# S32R372 register map
Vendor: Freescale Semiconductor, Inc.; Series: Qorivva; File version: 1.6
Registers are 32-bit, read-write, reset 0x0 unless marked. A register's access mark holds for its fields unless they carry their own. Offsets are from the block's base; [hi:lo] are bit positions; {n}, {i} and the like mark numbered series; 'fields as' and 'values as' point back to an identical list.

## PIT_1 — Periodic Interrupt Timer
Base 0xFFF80000; register names take the prefix PIT_1_
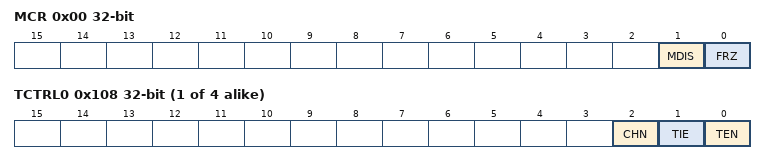
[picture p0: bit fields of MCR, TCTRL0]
0x00 MCR — PIT Module Control Register
  [1] MDIS — Module Disable - (PIT section)
    0=Clock for standard PIT timers is enabled; 1=Clock for standard PIT timers is disabled
  [0] FRZ — Freeze
    0=Timers continue to run in Debug mode; 1=Timers are stopped in Debug mode
0xE0 LTMR64H ro — PIT Upper Lifetime Timer Register
  [31:0] LTH — Life Timer value
0xE4 LTMR64L ro — PIT Lower Lifetime Timer Register
  [31:0] LTL — Life Timer value
{0x100+0x10*i} LDVAL{i} (i=0..3) — Timer Load Value Register
  [31:0] TSV — Timer Start Value
{0x104+0x10*i} CVAL{i} (i=0..3) ro — Current Timer Value Register
  [31:0] TVL — Current Timer Value
{0x108+0x10*i} TCTRL{i} (i=0..3) — Timer Control Register
  [2] CHN — Chain Mode
    0=Timer is not chained; 1=Timer is chained to previous timer. For example, for Channel 2, if this field is set, Timer 2 is chained to Timer 1.
  [1] TIE — Timer Interrupt Enable
    0=Interrupt requests from Timer n are disabled; 1=Interrupt will be requested whenever TIF is set
  [0] TEN — Timer Enable
    0=Timer n is disabled; 1=Timer n is enabled
{0x10C+0x10*i} TFLG{i} (i=0..3) — Timer Flag Register
  [0] TIF — Timer Interrupt Flag
    0=Timeout has not yet occurred; 1=Timeout has occurred

## PIT_0 — Periodic Interrupt Timer
Base 0xFFF84000; register names take the prefix PIT_0_
Registers as PIT_1.

## WKPU
Base 0xFFF98000; register names take the prefix WKPU_
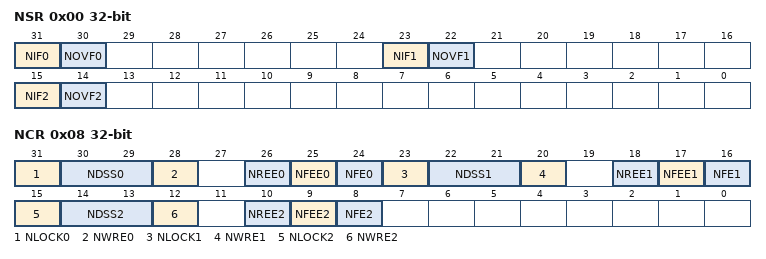
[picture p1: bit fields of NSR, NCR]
0x00 NSR — NMI Status Flag Register
  [31] NIF0 — NMI Status Flag 0
    0=No event has occurred on the pad; 1=An event as defined by NREE0 and NFEE0 has occurred
  [30] NOVF0 — NMI Overrun Status Flag 0
    0=No overrun has occurred on NMI input 0; 1=An overrun has occurred on NMI input 0
  [23] NIF1 — NMI Status Flag 1
    0=No event has occurred on the pad; 1=An event as defined by NREE1 and NFEE1 has occurred
  [22] NOVF1 — NMI Overrun Status Flag 1
    0=No overrun has occurred on NMI input 1; 1=An overrun has occurred on NMI input 1
  [15] NIF2 — NMI Status Flag 2
    0=No event has occurred on the pad; 1=An event as defined by NREE2 and NFEE2 has occurred
  [14] NOVF2 — NMI Overrun Status Flag 2
    0=No overrun has occurred on NMI input 2; 1=An overrun has occurred on NMI input 2
0x08 NCR — NMI Configuration Register
  [31] NLOCK0 — NMI Configuration Lock Register 0
  [30:29] NDSS0 — NMI Destination Source Select 0
    0=Non-maskable interrupt; 1=Critical interrupt; 2=Machine check request; 3=No NMI, critical Interrupt, or machine check request generated
  [28] NWRE0 — NMI Wakeup Request Enable 0 If wakeup requests are disabled, the corresponding NDSS field must be set to 11 to disable wakeups from an NMI, critical interrupt, or machine check
    0=System wakeup requests from the corresponding NIF0 bit are disabled; 1=A set NIF0 bit or set NOVF0 bit causes a system wakeup request
  [26] NREE0 — NMI Rising-edge Events Enable 0.
    0=Rising-edge event is disabled; 1=Rising-edge event is enabled
  [25] NFEE0 — NMI Falling-edge Events Enable 0.
    0=Falling-edge event is disabled; 1=Falling-edge event is enabled
  [24] NFE0 — NMI Filter Enable 0. Enable analog glitch filter on the NMI pad input.
    0=Filter is disabled; 1=Filter is enabled
  [23] NLOCK1 — NMI Configuration Lock Register 1
  [22:21] NDSS1 — NMI Destination Source Select 1
    values as NDSS0
  [20] NWRE1 — NMI Wakeup Request Enable 1
    0=System wakeup requests from the corresponding NIF1 bit are disabled; 1=A set NIF1 bit or set NOVF1 bit causes a system wakeup request
  [18] NREE1 — NMI Rising-edge Events Enable 1.
    values as NREE0
  [17] NFEE1 — NMI Falling-edge Events Enable 1.
    values as NFEE0
  [16] NFE1 — NMI Filter Enable 1. Enable analog glitch filter on the NMI pad input.
    0=Filter is disabled; 1=Filter is enabled
  [15] NLOCK2 — NMI Configuration Lock Register 2
  [14:13] NDSS2 — NMI Destination Source Select 2
    values as NDSS0
  [12] NWRE2 — NMI Wakeup Request Enable 2
    0=System wakeup requests from the corresponding NIF2 bit are disabled; 1=A set NIF2 bit or set NOVF2 bit causes a system wakeup request
  [10] NREE2 — NMI Rising-edge Events Enable 2.
    values as NREE0
  [9] NFEE2 — NMI Falling-edge Events Enable 2.
    values as NFEE0
  [8] NFE2 — NMI Filter Enable 2. Enable analog glitch filter on the NMI pad input.
    0=Filter is disabled; 1=Filter is enabled
